# STM32WBA62 register map
File version: 1.1
CPU: CM33 r0p1, little endian, MPU, FPU, 4 interrupt priority bits
Registers are 32-bit, read-write, reset 0x0 unless marked. A register's access mark holds for its fields unless they carry their own. Offsets are from the block's base; [hi:lo] are bit positions; {n}, {i} and the like mark numbered series.

## GPIOD — GPIOD address block description
Base 0x42020C00
Same registers: SEC_GPIOD 0x52020C00
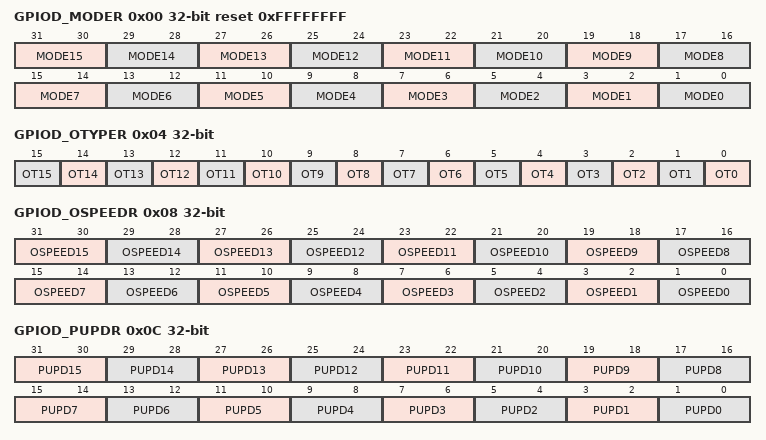
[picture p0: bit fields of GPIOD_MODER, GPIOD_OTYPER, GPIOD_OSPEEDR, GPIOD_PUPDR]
0x00 GPIOD_MODER reset 0xFFFFFFFF — GPIO port D mode register
  [31:30] MODE15 — Port configuration I/O pin 15
    0=Input mode; 1=General purpose output mode; 2=Alternate function mode; 3=Analog mode (reset state)
  [2n+1:2n] MODE{n} (n=0..14) — Port configuration I/O pin {n}
0x04 GPIOD_OTYPER — GPIO port D output type register
  [all] fields
    0=Output push-pull (reset state); 1=Output open-drain
  [n] OT{n} (n=0..15) — Port configuration I/O pin y
0x08 GPIOD_OSPEEDR — GPIO port D output speed register
  [31:30] OSPEED15 — Port configuration I/O pin 15
    0=Low speed; 1=Medium speed; 2=High speed
  [2n+1:2n] OSPEED{n} (n=0..14) — Port configuration I/O pin {n}
0x0C GPIOD_PUPDR — GPIO port D pull-up/pull-down register
  [31:30] PUPD15 — Port configuration I/O pin 15
    0=No pull-up, pull-down; 1=Pull-up; 2=Pull-down
  [2n+1:2n] PUPD{n} (n=0..14) — Port configuration I/O pin {n}
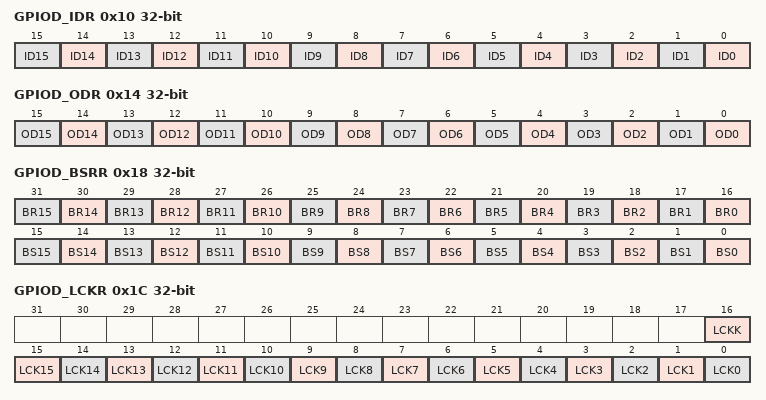
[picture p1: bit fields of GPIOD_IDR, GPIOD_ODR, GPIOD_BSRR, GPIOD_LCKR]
0x10 GPIOD_IDR ro (reset mask 0xFFFF0000) — GPIO port D input data register
  [n] ID{n} (n=0..15) — Port input data I/O pin y
0x14 GPIOD_ODR — GPIO port D output data register
  [n] OD{n} (n=0..15) — Port output data I/O pin y
0x18 GPIOD_BSRR wo — GPIO port D bit set/reset register
  [n+16] BR{n} (n=0..15) — Port reset I/O pin y
    0=No action on the corresponding ODy bit; 1=Resets the corresponding ODy bit
  [n] BS{n} (n=0..15) — Port set I/O pin y
    0=No action on the corresponding ODy bit; 1=Sets the corresponding ODy bit
0x1C GPIOD_LCKR — GPIO port D configuration lock register
  [16] LCKK — Lock key
    0=Port configuration lock key not active; 1=Port configuration lock key active
  [n] LCK{n} (n=0..15) — Port lock I/O pin y
    0=Port configuration not locked; 1=Port configuration locked
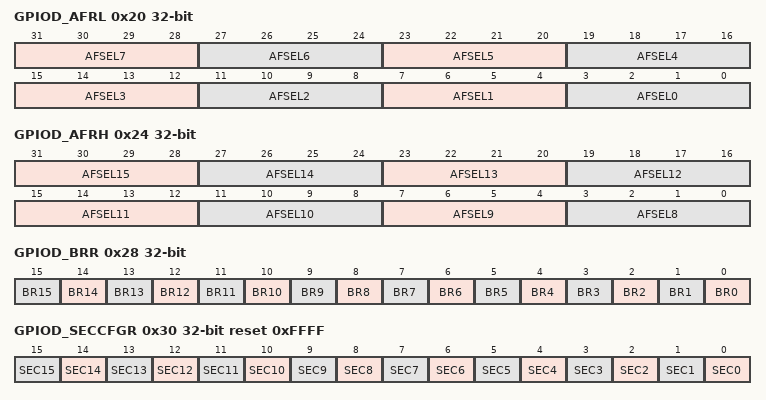
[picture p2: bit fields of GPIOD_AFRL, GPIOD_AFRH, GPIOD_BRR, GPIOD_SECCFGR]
0x20 GPIOD_AFRL — GPIO port D alternate function low register
  [31:28] AFSEL7 — Alternate function selection for port I/O pin 7
    {v}=AF{v} (v=0..15)
  [4n+3:4n] AFSEL{n} (n=0..6) — Alternate function selection for port I/O pin {n}
0x24 GPIOD_AFRH — GPIO port D alternate function high register
  [31:28] AFSEL15 — Alternate function selection for port I/O pin 15
    {v}=AF{v} (v=0..15)
  [4n-29:4n-32] AFSEL{n} (n=8..14) — Alternate function selection for port I/O pin {n}
0x28 GPIOD_BRR wo — GPIO port D bit reset register
  [all] fields
    0=No action on the corresponding ODy bit; 1=Reset the corresponding ODy bit
  [n] BR{n} (n=0..15) — Port reset I/O pin y
0x2C GPIOD_HSLVR — GPIO port D high-speed low-voltage register
  [14] HSLV14 — Port D high-speed low-voltage configuration
    0=I/O speed optimization disabled; 1=I/O speed optimization enabled
0x30 GPIOD_SECCFGR reset 0xFFFF — GPIO port D secure configuration register
  [all] fields
    0=The I/O pin is non-secure; 1=The I/O pin is secure
  [n] SEC{n} (n=0..15) — I/O pin of port secure bit enable y

## GPIOE — GPIOE address block description
Base 0x42021000
Same registers: SEC_GPIOE 0x52021000
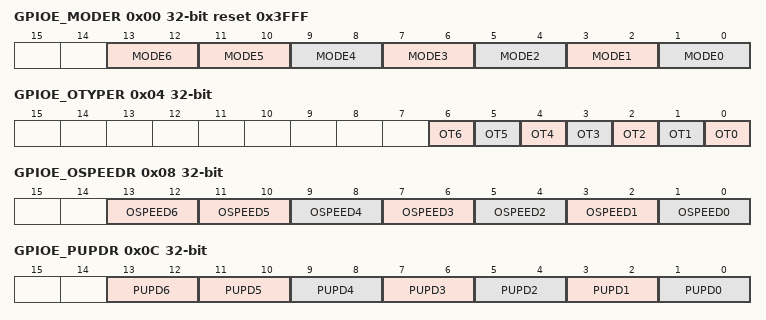
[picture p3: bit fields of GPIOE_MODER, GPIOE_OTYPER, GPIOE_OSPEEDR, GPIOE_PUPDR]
0x00 GPIOE_MODER reset 0x3FFF — GPIO port E mode register
  [13:12] MODE6 — Port configuration I/O pin 6
    0=Input mode; 1=General purpose output mode; 2=Alternate function mode; 3=Analog mode (reset state)
  [2n+1:2n] MODE{n} (n=0..5) — Port configuration I/O pin {n}
0x04 GPIOE_OTYPER — GPIO port E output type register
  [all] fields
    0=Output push-pull (reset state); 1=Output open-drain
  [n] OT{n} (n=0..6) — Port configuration I/O pin y
0x08 GPIOE_OSPEEDR — GPIO port E output speed register
  [13:12] OSPEED6 — Port configuration I/O pin 6
    0=Low speed; 1=Medium speed; 2=High speed
  [2n+1:2n] OSPEED{n} (n=0..5) — Port configuration I/O pin {n}
0x0C GPIOE_PUPDR — GPIO port E pull-up/pull-down register
  [13:12] PUPD6 — Port configuration I/O pin 6
    0=No pull-up, pull-down; 1=Pull-up; 2=Pull-down
  [2n+1:2n] PUPD{n} (n=0..5) — Port configuration I/O pin {n}
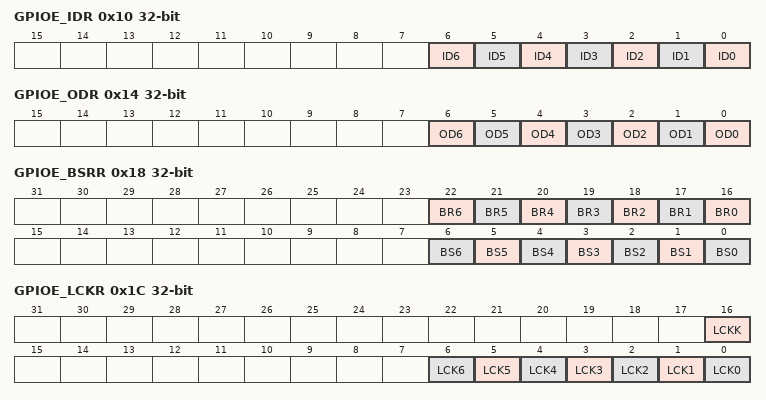
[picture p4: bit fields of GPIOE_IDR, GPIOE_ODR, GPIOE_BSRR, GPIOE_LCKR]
0x10 GPIOE_IDR ro (reset mask 0xFFFF0000) — GPIO port E input data register
  [n] ID{n} (n=0..6) — Port input data I/O pin y
0x14 GPIOE_ODR — GPIO port E output data register
  [n] OD{n} (n=0..6) — Port output data I/O pin y
0x18 GPIOE_BSRR wo — GPIO port E bit set/reset register
  [n+16] BR{n} (n=0..6) — Port reset I/O pin y
    0=No action on the corresponding ODy bit; 1=Resets the corresponding ODy bit
  [n] BS{n} (n=0..6) — Port set I/O pin y
    0=No action on the corresponding ODy bit; 1=Sets the corresponding ODy bit
0x1C GPIOE_LCKR — GPIO port E configuration lock register
  [16] LCKK — Lock key
    0=Port configuration lock key not active; 1=Port configuration lock key active
  [n] LCK{n} (n=0..6) — Port lock I/O pin y
    0=Port configuration not locked; 1=Port configuration locked
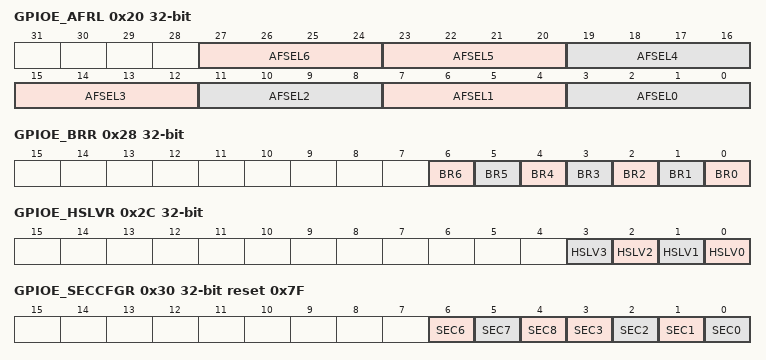
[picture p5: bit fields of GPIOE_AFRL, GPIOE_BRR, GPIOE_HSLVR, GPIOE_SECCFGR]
0x20 GPIOE_AFRL — GPIO port E alternate function low register
  [27:24] AFSEL6 — Alternate function selection for port I/O pin 6
    {v}=AF{v} (v=0..15)
  [4n+3:4n] AFSEL{n} (n=0..5) — Alternate function selection for port I/O pin {n}
0x28 GPIOE_BRR wo — GPIO port E bit reset register
  [all] fields
    0=No action on the corresponding ODy bit; 1=Reset the corresponding ODy bit
  [n] BR{n} (n=0..6) — Port reset I/O pin y
0x2C GPIOE_HSLVR — GPIO port E high-speed low-voltage register
  [all] fields
    0=I/O speed optimization disabled; 1=I/O speed optimization enabled
  [n] HSLV{n} (n=0..3) — Port E high-speed low-voltage configuration
0x30 GPIOE_SECCFGR reset 0x7F — GPIO port E secure configuration register
  [6] SEC6 — I/O pin of port secure bit enable y
    0=The I/O pin is non-secure; 1=The I/O pin is secure
  [5] SEC7 — I/O pin of port secure bit enable y
    0=The I/O pin is non-secure; 1=The I/O pin is secure
  [4] SEC8 — I/O pin of port secure bit enable y
    0=The I/O pin is non-secure; 1=The I/O pin is secure
  [n] SEC{n} (n=0..3) — I/O pin of port secure bit enable y
    0=The I/O pin is nonsecure; 1=The I/O pin is secure
